# STM32WBA63xx register map
File version: 1.0
Registers are 32-bit, read-write, reset 0x0 unless marked. A register's access mark holds for its fields unless they carry their own. Offsets are from the block's base; [hi:lo] are bit positions; {n}, {i} and the like mark numbered series.

## GTZC_MPCBB1
Base 0x40032C00
Same registers: GTZC_MPCBB2 0x40033000, GTZC_MPCBB6 0x40034000
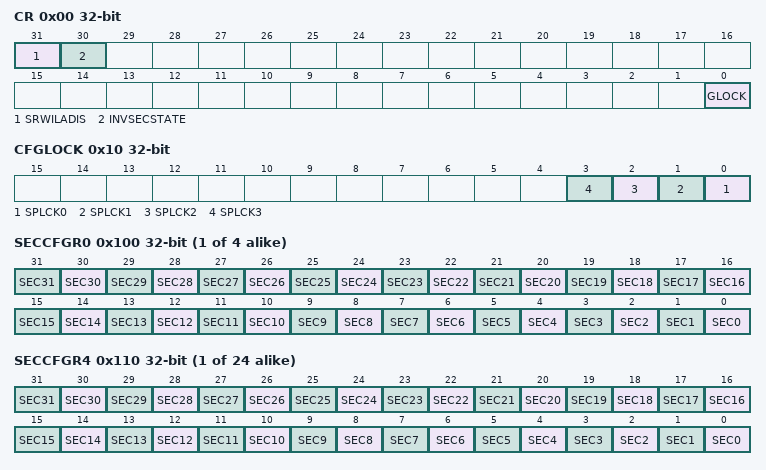
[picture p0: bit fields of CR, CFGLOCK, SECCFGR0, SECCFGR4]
0x00 CR — MPCBBx control register
  [31] SRWILADIS — secure read/write illegal access disable
  [30] INVSECSTATE — SRAM clocks security state
  [0] GLOCK — lock the control register of the MPCBB until next reset
0x10 CFGLOCK — MPCBBx lock register
  [n] SPLCK{n} (n=0..3) — Security/privilege configuration lock super-block {n}
{0x100+4i} SECCFGR{i} (i=0..3) — MPCBBx security configuration registers
  [n] SEC{n} (n=0..31) — Security configuration for block {n} in super block {i}
{0x100+4i} SECCFGR{i} (i=4..27) — MPCBBx security configuration registers
  [n] SEC{n} (n=0..31) — Security configuration for block {n} in super block 0
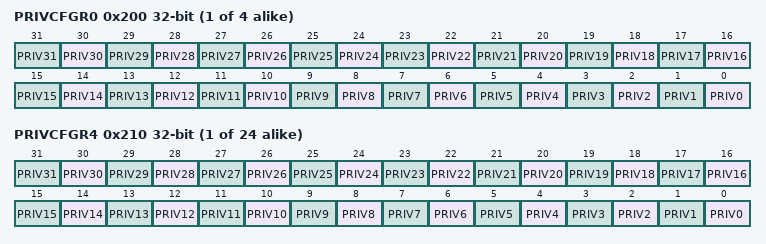
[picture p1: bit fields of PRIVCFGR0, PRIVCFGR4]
{0x200+4i} PRIVCFGR{i} (i=0..3) — MPCBBx privilege configuration registers
  [n] PRIV{n} (n=0..31) — Privileged configuration for block {n} in super block {i}
{0x200+4i} PRIVCFGR{i} (i=4..27) — MPCBBx privilege configuration registers
  [n] PRIV{n} (n=0..31) — Privileged configuration for block {n} in super block 0

## GPIOA — General Purpose I/O
Base 0x42020000
Same registers: GPIOB 0x42020400, GPIOC 0x42020800, GPIOH 0x42021C00
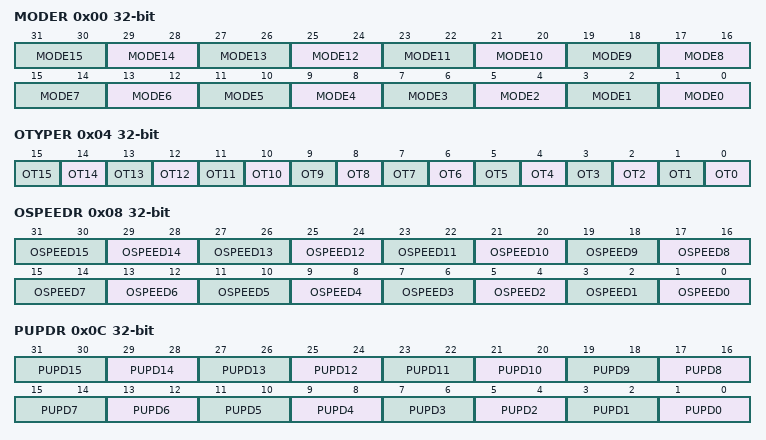
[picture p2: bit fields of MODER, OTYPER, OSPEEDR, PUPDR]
0x00 MODER — GPIO port mode register
  [2n+1:2n] MODE{n} (n=0..15)
0x04 OTYPER — GPIO port output type register
  [n] OT{n} (n=0..15)
0x08 OSPEEDR — GPIO port output speed register
  [2n+1:2n] OSPEED{n} (n=0..15)
0x0C PUPDR — GPIO port pull-up/pull-down register
  [2n+1:2n] PUPD{n} (n=0..15)
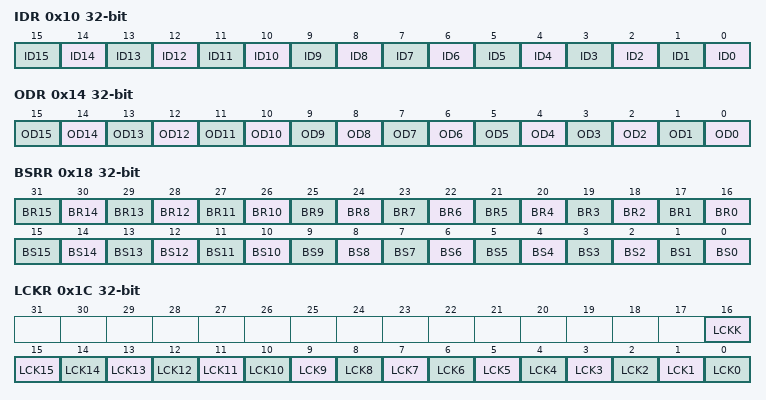
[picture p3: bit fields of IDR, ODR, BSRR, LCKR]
0x10 IDR — GPIO port input data register
  [n] ID{n} (n=0..15)
0x14 ODR — GPIO port output data register
  [n] OD{n} (n=0..15)
0x18 BSRR — GPIO port bit set/reset register
  [n+16] BR{n} (n=0..15), [n] BS{n} (n=0..15)
0x1C LCKR — GPIO port configuration lock register
  [16] LCKK, [n] LCK{n} (n=0..15)
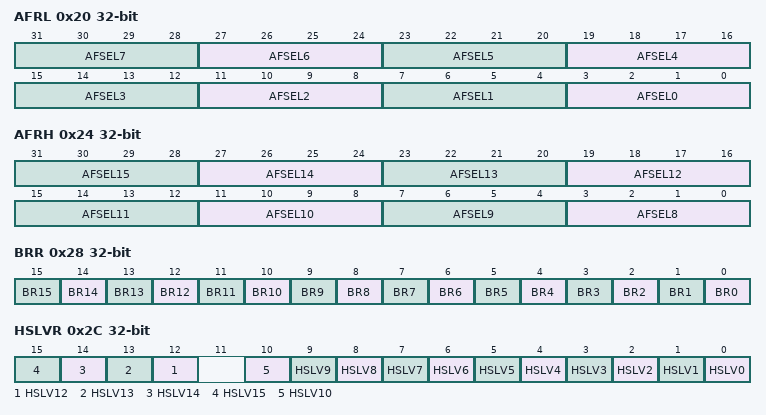
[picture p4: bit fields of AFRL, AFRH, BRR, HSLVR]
0x20 AFRL — GPIO alternate function registers
  [4n+3:4n] AFSEL{n} (n=0..7)
0x24 AFRH — GPIO alternate function registers
  [4n-29:4n-32] AFSEL{n} (n=8..15)
0x28 BRR — GPIO Bit Reset register
  [n] BR{n} (n=0..15)
0x2C HSLVR — GPIO high-speed low voltage register
  [n] HSLV{n} (n=12..15), [n] HSLV{n} (n=0..10)
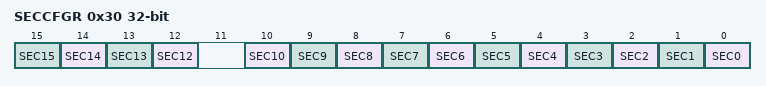
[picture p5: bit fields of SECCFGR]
0x30 SECCFGR — GPIO secure configuration register
  [n] SEC{n} (n=12..15), [n] SEC{n} (n=0..10)

## AES — AES hardware accelerator
Base 0x420C0000
Same registers: SAES 0x420C0C00
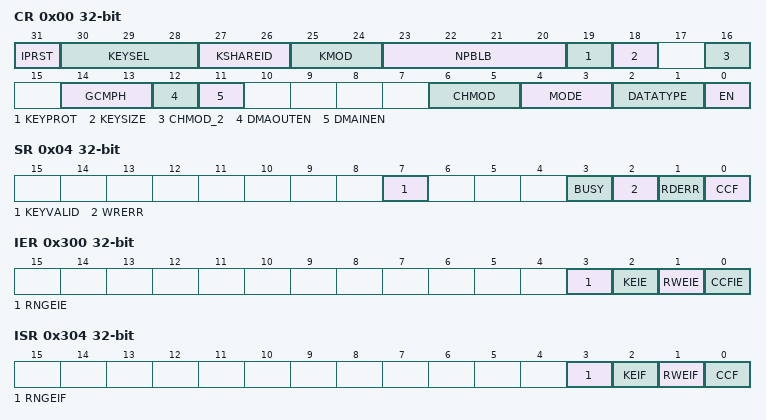
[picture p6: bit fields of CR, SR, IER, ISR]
0x00 CR — AES control register
  [31] IPRST — AES IP software reset
  [30:28] KEYSEL — Key Selection
  [27:26] KSHAREID — Key Shared ID
  [25:24] KMOD — Key mode selection
  [23:20] NPBLB — Number of padding bytes in payload last block
  [19] KEYPROT — Key protection
  [18] KEYSIZE — Key size selection
  [16] CHMOD_2 — AES Chaining Mode
  [14:13] GCMPH — GCM Phase
  [12] DMAOUTEN — Enable data output phase DMA management
  [11] DMAINEN — Enable data input phase DMA management
  [6:5] CHMOD — AES Chaining Mode
  [4:3] MODE — AES Mode Of Operation
  [2:1] DATATYPE — Data type selection
  [0] EN — AES Enable
0x04 SR — AES status register
  [7] KEYVALID — Key Valid Flag
  [3] BUSY — Busy Flag
  [2] WRERR — Write Error Flag
  [1] RDERR — Read Error Flag
  [0] CCF — Computation Complete Flag
0x08 DINR — AES data input register
  [31:0] DINR — AES Data Input Register
0x0C DOUTR — AES data output register
  [31:0] DOUTR — AES Data Output Register
{0x10+4i} KEYR{i} (i=0..3) — AES key register {i}
  [31:0] KEYR{i} — AES Key Register {i}
{0x20+4i} IVR{i} (i=0..3) — AES initialization vector register {i}
  [31:0] IVR{i} — AES Initialization Vector Register {i}
{0x20+4i} KEYR{i} (i=4..7) — AES key register {i}
  [31:0] KEYR{i} — AES Key Register {i}
{0x40+4i} SUSP{i}R (i=0..7) — AES Suspend register {i}
  [31:0] SUSP{i}R — AES Suspend registers {i}
0x300 IER — AES Interrupt Enable Register
  [3] RNGEIE — SAES Rng error interrupt enable
  [2] KEIE — Key error interrupt enable
  [1] RWEIE — Read or write error Interrupt Enable
  [0] CCFIE — Computation complete flag interrupt enable
0x304 ISR — AES Interrupt Status Register
  [3] RNGEIF — SAES Rng error interrupt flag
  [2] KEIF — Key error interrupt flag
  [1] RWEIF — Read or write error Interrupt flag
  [0] CCF — Computation complete flag
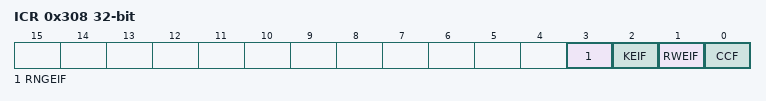
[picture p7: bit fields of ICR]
0x308 ICR — AES Interrupt Clear Register
  [3] RNGEIF — SAES Rng error interrupt flag clear
  [2] KEIF — Key error interrupt flag clear
  [1] RWEIF — Read or write error Interrupt flag clear
  [0] CCF — Computation complete flag clear
